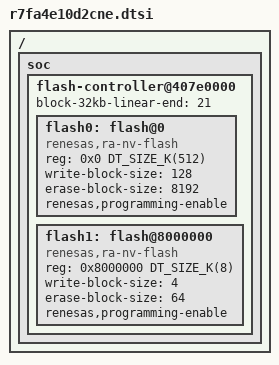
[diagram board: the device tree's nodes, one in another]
/*
 * Copyright (c) 2025 Renesas Electronics Corporation
 *
 * SPDX-License-Identifier: Apache-2.0
 */

#include <zephyr/dt-bindings/clock/ra_clock.h>
#include <arm/renesas/ra/ra4/r7fa4e10x.dtsi>

/ {
	soc {
		flash-controller@407e0000 {
			block-32kb-linear-end = <21>;

			flash0: flash@0 {
				compatible = "renesas,ra-nv-flash";
				reg = <0x0 DT_SIZE_K(512)>;
				write-block-size = <128>;
				erase-block-size = <8192>;
				renesas,programming-enable;
			};

			flash1: flash@8000000 {
				compatible = "renesas,ra-nv-flash";
				reg = <0x8000000 DT_SIZE_K(8)>;
				write-block-size = <4>;
				erase-block-size = <64>;
				renesas,programming-enable;
			};
		};
	};
};
